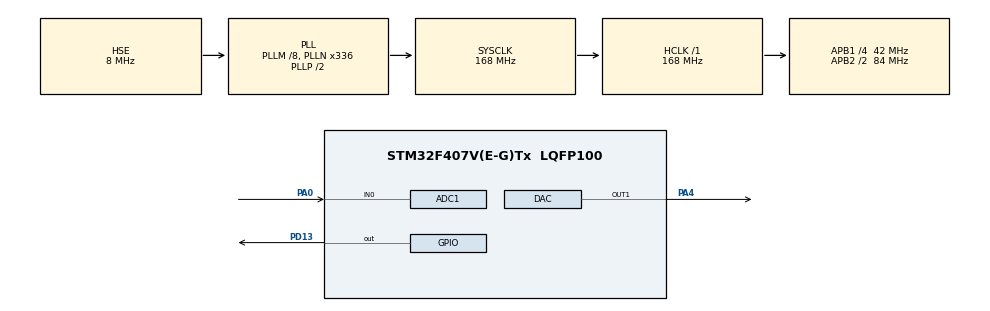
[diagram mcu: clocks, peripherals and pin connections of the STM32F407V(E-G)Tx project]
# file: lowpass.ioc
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ADC1.Channel-0\#ChannelRegularConversion=ADC_CHANNEL_0
ADC1.NbrOfConversionFlag=1
ADC1.Rank-0\#ChannelRegularConversion=1
ADC1.SamplingTime-0\#ChannelRegularConversion=ADC_SAMPLETIME_3CYCLES
ADC1.master=1
Dma.DAC1.0.Direction=DMA_MEMORY_TO_PERIPH
Dma.DAC1.0.FIFOMode=DMA_FIFOMODE_DISABLE
Dma.DAC1.0.Instance=DMA1_Stream5
Dma.DAC1.0.MemDataAlignment=DMA_MDATAALIGN_WORD
Dma.DAC1.0.MemInc=DMA_MINC_ENABLE
Dma.DAC1.0.Mode=DMA_CIRCULAR
Dma.DAC1.0.PeriphDataAlignment=DMA_PDATAALIGN_WORD
Dma.DAC1.0.PeriphInc=DMA_PINC_DISABLE
Dma.DAC1.0.Priority=DMA_PRIORITY_LOW
Dma.Request0=DAC1
Mcu.Family=STM32F4
Mcu.Name=STM32F407V(E-G)Tx
Mcu.Package=LQFP100
NVIC.DMA1_Stream5_IRQn=true\:0\:0\:false\:false\:true\:false\:true\:true
NVIC.PriorityGroup=NVIC_PRIORITYGROUP_0
NVIC.TIM6_DAC_IRQn=true\:0\:0\:false\:false\:true\:true\:true\:true
PA0-WKUP.Signal=ADCx_IN0
PA4.Signal=COMP_DAC1_group
PC14-OSC32_IN.Mode=LSE-External-Oscillator
PC14-OSC32_IN.Signal=RCC_OSC32_IN
PC15-OSC32_OUT.Mode=LSE-External-Oscillator
PC15-OSC32_OUT.Signal=RCC_OSC32_OUT
PD13.Signal=GPIO_Output
PH0-OSC_IN.Mode=HSE-External-Oscillator
PH0-OSC_IN.Signal=RCC_OSC_IN
PH1-OSC_OUT.Mode=HSE-External-Oscillator
PH1-OSC_OUT.Signal=RCC_OSC_OUT
ProjectManager.HeapSize=0x200
ProjectManager.StackSize=0x400
ProjectManager.TargetToolchain=STM32CubeIDE
RCC.48MHZClocksFreq_Value=48000000
RCC.AHBFreq_Value=168000000
RCC.APB1CLKDivider=RCC_HCLK_DIV4
RCC.APB1Freq_Value=42000000
RCC.APB1TimFreq_Value=84000000
RCC.APB2CLKDivider=RCC_HCLK_DIV2
RCC.APB2Freq_Value=84000000
RCC.APB2TimFreq_Value=168000000
RCC.CortexFreq_Value=168000000
RCC.HCLKFreq_Value=168000000
RCC.HSE_VALUE=8000000
RCC.HSI_VALUE=16000000
RCC.PLLM=8
RCC.PLLN=336
RCC.PLLQ=7
RCC.PLLSourceVirtual=RCC_PLLSOURCE_HSE
RCC.SYSCLKFreq_VALUE=168000000
RCC.SYSCLKSource=RCC_SYSCLKSOURCE_PLLCLK
RCC.VCOOutputFreq_Value=336000000
SH.ADCx_IN0.0=ADC1_IN0,IN0
SH.COMP_DAC1_group.0=DAC_OUT1,DAC_OUT1
TIM6.Period=999
TIM6.Prescaler=83
VP_TIM6_VS_ClockSourceINT.Mode=Enable_Timer
board=STM32F407G-DISC1

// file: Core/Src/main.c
/* USER CODE BEGIN Header */
/**
  ******************************************************************************
  * @file           : main.c
  * @brief          : Main program body
  ******************************************************************************
  * @attention
  *
  * Copyright (c) 2023 STMicroelectronics.
  * All rights reserved.
  *
  * This software is licensed under terms that can be found in the LICENSE file
  * in the root directory of this software component.
  * If no LICENSE file comes with this software, it is provided AS-IS.
  *
  ******************************************************************************
  */
/* USER CODE END Header */
#include "main.h"

ADC_HandleTypeDef hadc1;

DAC_HandleTypeDef hdac;
DMA_HandleTypeDef hdma_dac1;

TIM_HandleTypeDef htim6;

/* USER CODE BEGIN PV */

//Initialize the timer interrupt function
void HAL_TIM_PeriodElapsedCallback(TIM_HandleTypeDef *htim);

/* USER CODE END PV */

void SystemClock_Config(void);
static void MX_GPIO_Init(void);
static void MX_DMA_Init(void);
static void MX_TIM6_Init(void);
static void MX_ADC1_Init(void);
static void MX_DAC_Init(void);

/* USER CODE BEGIN 0 */

//define analog values and valbyte for dac
uint16_t adcVal;
uint16_t valByte;

//define adc flag for timer interrupt when interrupt is call the flag value is set 1
uint16_t adc_flag = 0;

float e_t=0,e_t1=0,e_t2=0,r_t=0,r_t1=0,r_t2=0,r_dac;

//define the a and b coefficient value for transfer function
float b= -0.96906742,a=0.01546629;  //low pass
//float b= -0.96906742,a= 0.98453371;
/* USER CODE END 0 */

int main(void)
{

  /* MCU Configuration--------------------------------------------------------*/

  /* Reset of all peripherals, Initializes the Flash interface and the Systick. */
  HAL_Init();

  /* Configure the system clock */
  SystemClock_Config();

  /* Initialize all configured peripherals */
  MX_GPIO_Init();
  MX_DMA_Init();
  MX_TIM6_Init();
  MX_ADC1_Init();
  MX_DAC_Init();
  /* USER CODE BEGIN 2 */

//start timer interrupt and ADC
HAL_TIM_Base_Start_IT(&htim6);
HAL_ADC_Start(&hadc1);

  /* USER CODE END 2 */

  /* Infinite loop */
  /* USER CODE BEGIN WHILE */

//define the transfer function variables
float x,y,x1=0,y1=0,y2;

  while (1)
  {
	  //start ADC and get ADC value in adcval as input the ADC channel 1 is PA0
	  HAL_ADC_Start(&hadc1);
	  adcVal= HAL_ADC_GetValue(&hadc1);

	//put the condition of adc flag is 1
     if(adc_flag == 1)
      {
		//first initialize the adc flag to 0
		 adc_flag=0;
			  //valByte=adcVal;

		//store ADC value in x and convert ADC value to voltage value
		  e_t = (adcVal*3.0f)/4095;
		  x=e_t;
		//write the transfer function equation y(z) = -b*y(z-1)+a*x(z)+a*x(z-1)
		  y=-b*y1+a*x+a*x1;
		//hear if you with you can give the 1.5f shift then you get signal between 0 to 3 v
		  y2= y;
		//convert the voltage value to the ADC values
		  valByte = (y2/3.0f)*4095;

		//		  r_dac=r_t+1.5f;
		//		  valByte = (r_dac/3.0f)*4095;
		//		  e_t1=e_t;
		//		  r_t1=r_t;

		//store the value of variables
		  x1=x;
		  y1=y;
		//start the DAC and set DAC values the out put is DAC 1 is connected to the PA4
		  HAL_DAC_Start(&hdac, DAC_CHANNEL_1);
		  HAL_DAC_SetValue(&hdac, DAC1_CHANNEL_1, DAC1_CHANNEL_1, valByte);
  }
    /* USER CODE END WHILE */

    /* USER CODE BEGIN 3 */
	  //HAL_Delay(100);

  }
  /* USER CODE END 3 */
}
//write the timer interrupt function
void HAL_TIM_PeriodElapsedCallback(TIM_HandleTypeDef *htim)
{
	adc_flag=1;
}
void SystemClock_Config(void)
{
  RCC_OscInitTypeDef RCC_OscInitStruct = {0};
  RCC_ClkInitTypeDef RCC_ClkInitStruct = {0};

  /** Configure the main internal regulator output voltage
  */
  __HAL_RCC_PWR_CLK_ENABLE();
  __HAL_PWR_VOLTAGESCALING_CONFIG(PWR_REGULATOR_VOLTAGE_SCALE1);

  /** Initializes the RCC Oscillators according to the specified parameters
  * in the RCC_OscInitTypeDef structure.
  */
  RCC_OscInitStruct.OscillatorType = RCC_OSCILLATORTYPE_HSE;
  RCC_OscInitStruct.HSEState = RCC_HSE_ON;
  RCC_OscInitStruct.PLL.PLLState = RCC_PLL_ON;
  RCC_OscInitStruct.PLL.PLLSource = RCC_PLLSOURCE_HSE;
  RCC_OscInitStruct.PLL.PLLM = 8;
  RCC_OscInitStruct.PLL.PLLN = 336;
  RCC_OscInitStruct.PLL.PLLP = RCC_PLLP_DIV2;
  RCC_OscInitStruct.PLL.PLLQ = 7;
  if (HAL_RCC_OscConfig(&RCC_OscInitStruct) != HAL_OK)
  {
    Error_Handler();
  }

  /** Initializes the CPU, AHB and APB buses clocks
  */
  RCC_ClkInitStruct.ClockType = RCC_CLOCKTYPE_HCLK|RCC_CLOCKTYPE_SYSCLK
                              |RCC_CLOCKTYPE_PCLK1|RCC_CLOCKTYPE_PCLK2;
  RCC_ClkInitStruct.SYSCLKSource = RCC_SYSCLKSOURCE_PLLCLK;
  RCC_ClkInitStruct.AHBCLKDivider = RCC_SYSCLK_DIV1;
  RCC_ClkInitStruct.APB1CLKDivider = RCC_HCLK_DIV4;
  RCC_ClkInitStruct.APB2CLKDivider = RCC_HCLK_DIV2;

  if (HAL_RCC_ClockConfig(&RCC_ClkInitStruct, FLASH_LATENCY_5) != HAL_OK)
  {
    Error_Handler();
  }
}

static void MX_ADC1_Init(void)
{

  ADC_ChannelConfTypeDef sConfig = {0};

  /** Configure the global features of the ADC (Clock, Resolution, Data Alignment and number of conversion)
  */
  hadc1.Instance = ADC1;
  hadc1.Init.ClockPrescaler = ADC_CLOCK_SYNC_PCLK_DIV4;
  hadc1.Init.Resolution = ADC_RESOLUTION_12B;
  hadc1.Init.ScanConvMode = DISABLE;
  hadc1.Init.ContinuousConvMode = DISABLE;
  hadc1.Init.DiscontinuousConvMode = DISABLE;
  hadc1.Init.ExternalTrigConvEdge = ADC_EXTERNALTRIGCONVEDGE_NONE;
  hadc1.Init.ExternalTrigConv = ADC_SOFTWARE_START;
  hadc1.Init.DataAlign = ADC_DATAALIGN_RIGHT;
  hadc1.Init.NbrOfConversion = 1;
  hadc1.Init.DMAContinuousRequests = DISABLE;
  hadc1.Init.EOCSelection = ADC_EOC_SINGLE_CONV;
  if (HAL_ADC_Init(&hadc1) != HAL_OK)
  {
    Error_Handler();
  }

  /** Configure for the selected ADC regular channel its corresponding rank in the sequencer and its sample time.
  */
  sConfig.Channel = ADC_CHANNEL_0;
  sConfig.Rank = 1;
  sConfig.SamplingTime = ADC_SAMPLETIME_3CYCLES;
  if (HAL_ADC_ConfigChannel(&hadc1, &sConfig) != HAL_OK)
  {
    Error_Handler();
  }

}

static void MX_DAC_Init(void)
{

  DAC_ChannelConfTypeDef sConfig = {0};

  /** DAC Initialization
  */
  hdac.Instance = DAC;
  if (HAL_DAC_Init(&hdac) != HAL_OK)
  {
    Error_Handler();
  }

  /** DAC channel OUT1 config
  */
  sConfig.DAC_Trigger = DAC_TRIGGER_NONE;
  sConfig.DAC_OutputBuffer = DAC_OUTPUTBUFFER_ENABLE;
  if (HAL_DAC_ConfigChannel(&hdac, &sConfig, DAC_CHANNEL_1) != HAL_OK)
  {
    Error_Handler();
  }

}

static void MX_TIM6_Init(void)
{

  TIM_MasterConfigTypeDef sMasterConfig = {0};

  htim6.Instance = TIM6;
  htim6.Init.Prescaler = 83;
  htim6.Init.CounterMode = TIM_COUNTERMODE_UP;
  htim6.Init.Period = 9;
  htim6.Init.AutoReloadPreload = TIM_AUTORELOAD_PRELOAD_DISABLE;
  if (HAL_TIM_Base_Init(&htim6) != HAL_OK)
  {
    Error_Handler();
  }
  sMasterConfig.MasterOutputTrigger = TIM_TRGO_RESET;
  sMasterConfig.MasterSlaveMode = TIM_MASTERSLAVEMODE_DISABLE;
  if (HAL_TIMEx_MasterConfigSynchronization(&htim6, &sMasterConfig) != HAL_OK)
  {
    Error_Handler();
  }

}

static void MX_DMA_Init(void)
{

  /* DMA controller clock enable */
  __HAL_RCC_DMA1_CLK_ENABLE();

  /* DMA interrupt init */
  /* DMA1_Stream5_IRQn interrupt configuration */
  HAL_NVIC_SetPriority(DMA1_Stream5_IRQn, 0, 0);
  HAL_NVIC_EnableIRQ(DMA1_Stream5_IRQn);

}

static void MX_GPIO_Init(void)
{
  GPIO_InitTypeDef GPIO_InitStruct = {0};

  /* GPIO Ports Clock Enable */
  __HAL_RCC_GPIOC_CLK_ENABLE();
  __HAL_RCC_GPIOH_CLK_ENABLE();
  __HAL_RCC_GPIOA_CLK_ENABLE();
  __HAL_RCC_GPIOD_CLK_ENABLE();

  /*Configure GPIO pin Output Level */
  HAL_GPIO_WritePin(GPIOD, GPIO_PIN_13, GPIO_PIN_RESET);

  /*Configure GPIO pin : PD13 */
  GPIO_InitStruct.Pin = GPIO_PIN_13;
  GPIO_InitStruct.Mode = GPIO_MODE_OUTPUT_PP;
  GPIO_InitStruct.Pull = GPIO_NOPULL;
  GPIO_InitStruct.Speed = GPIO_SPEED_FREQ_LOW;
  HAL_GPIO_Init(GPIOD, &GPIO_InitStruct);

}

void Error_Handler(void)
{
  __disable_irq();
  while (1)
  {
  }
}
